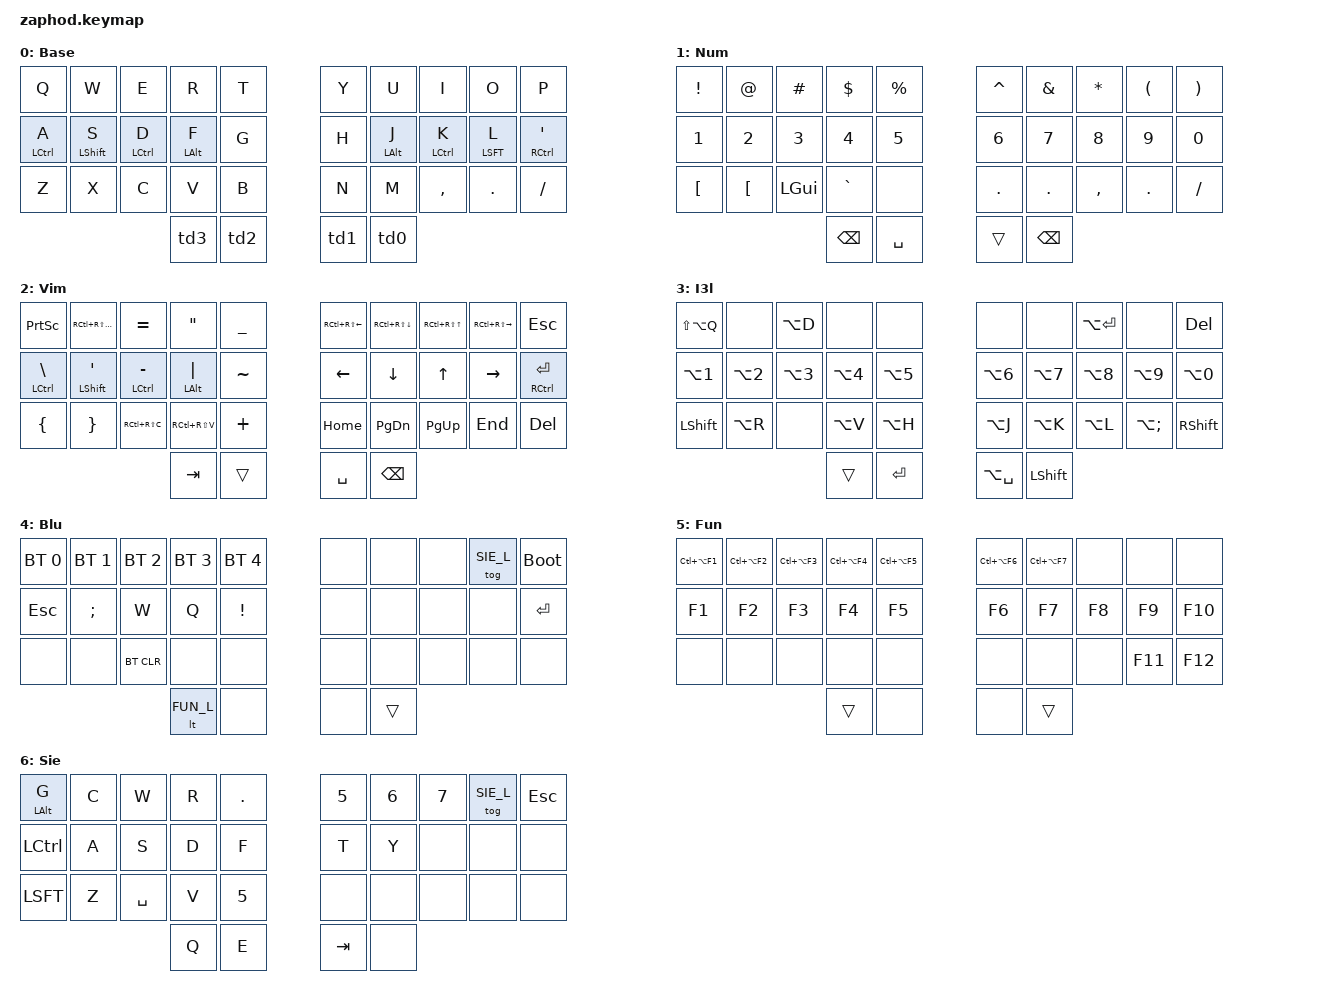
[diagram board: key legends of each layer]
/*
 * Copyright (c) 2021 Pete Johanson
 *
 * SPDX-License-Identifier: MIT
 */

#include <behaviors.dtsi>
#include <dt-bindings/zmk/keys.h>
#include <dt-bindings/zmk/bt.h>
#include <dt-bindings/zmk/outputs.h>

#define NUM_L 1
#define VIM_L 2
#define I3L_L 3
#define BLU_L 4
#define FUN_L 5
#define SIE_L 6

// Using layer taps on thumbs, having quick tap as well helps w/ repeating space/backspace
&lt { quick_tap_ms = <200>; };

/ {
    combos {
        compatible = "zmk,combos";

/*        med_mo {
 *	    timeout-ms = <50>;
 *          key-positions = <30 31>;
 *          bindings = <&mo MED_L>;
 *       };
 *
 *        fn_mo {
 *	    timeout-ms = <50>;
 *          key-positions = <32 33>;
 *          bindings = <&mo FUN_L>;
 *       };
 */
    };

    behaviors {
        hm: homerow_mods {
            compatible = "zmk,behavior-hold-tap";
            label = "homerow mods";
            #binding-cells = <2>;
            tapping_term_ms = <200>;
            flavor = "tap-preferred";
            bindings = <&kp>, <&kp>;
        };
            
        td0: tap_dance_0 {
            compatible = "zmk,behavior-tap-dance";
            label = "TAP_DANCE_0";
            #binding-cells = <0>;
            tapping-term-ms = <200>;
            bindings = <&lt BLU_L BKSP>, <&kp BKSP>;
        };
        
        td1: tap_dance_1 {
            compatible = "zmk,behavior-tap-dance";
            label = "TAP_DANCE_1";
            #binding-cells = <0>;
            tapping-term-ms = <200>;
            bindings = <&lt NUM_L SPACE>, <&kp SPACE>;
        };

        td2: tap_dance_2 {
            compatible = "zmk,behavior-tap-dance";
            label = "TAP_DANCE_2";
            #binding-cells = <0>;
            tapping-term-ms = <200>;
            bindings = <&lt VIM_L RET>, <&kp RET>;
        };

        td3: tap_dance_3 {
            compatible = "zmk,behavior-tap-dance";
            label = "TAP_DANCE_3";
            #binding-cells = <0>;
            tapping-term-ms = <200>;
            bindings = <&lt I3L_L TAB>, <&kp TAB>;
        };
    };

    keymap {
        compatible = "zmk,keymap";

        default_layer {
            label = "Base";
            bindings = <
                &kp Q       &kp W      &kp E       &kp R          &kp T         &kp Y            &kp U          &kp I       &kp O      &kp P
                &hm LCTRL A &hm LSHFT S &hm LCTRL D &hm LALT F    &kp G         &kp H            &hm LALT J     &hm LCTRL K &hm LSFT L &hm RCTRL QUOT
                &kp Z       &kp X      &kp C       &kp V          &kp B         &kp N            &kp M          &kp COMMA   &kp DOT    &kp FSLH
                                                   &td3           &td2          &td1             &td0
            >;
        };

        NUM_layer {
            label = "Num";
            bindings = <
                &kp EXCL  &kp AT    &kp POUND  &kp DLLR       &kp PRCNT   &kp CARET       &kp AMPS      &kp ASTRK  &kp LPAR  &kp RPAR
                &kp N1    &kp N2    &kp N3     &kp N4         &kp N5      &kp N6          &kp N7        &kp N8     &kp N9    &kp N0 
                &kp LBKT  &kp LBKT  &kp LGUI   &kp GRAVE      &none       &kp DOT         &kp DOT       &kp COMMA  &kp DOT   &kp FSLH
                                               &kp BKSP       &kp SPACE	  &trans          &kp BKSP
            >;
        };

        VIM_layer {
            label = "Vim";
            bindings = <
&kp PSCRN    &kp RC(RS(PSCRN)) &kp EQUAL         &kp DQT       &kp UNDER  &kp RC(RS(LEFT)) &kp RC(RS(DOWN)) &kp RC(RS(UP)) &kp RC(RS(RIGHT)) &kp ESC
&hm LCTRL BSLH  &hm LSHFT SQT  &hm LCTRL MINUS   &hm LALT PIPE &kp TILDE  &kp LEFT        &kp DOWN      &kp UP           &kp RIGHT       &hm RCTRL ENTER     
  &kp LBRC   &kp RBRC          &kp RC(RS(C))     &kp RC(RS(V)) &kp PLUS   &kp HOME        &kp PG_DN     &kp PG_UP        &kp END         &kp DEL   
                                               &kp TAB         &trans     &kp SPACE       &kp BKSP
            >;
        };

        I3L_layer {
            label = "I3l";
            bindings = <
            &kp LS(LA(Q)) &none     &kp LA(D) &none          &none        &none          &none         &kp LA(RET) &none     &kp DEL
               &kp LA(N1) &kp LA(N2) &kp LA(N3) &kp LA(N4)   &kp LA(N5)   &kp LA(N6)     &kp LA(N7)    &kp LA(N8) &kp LA(N9) &kp LA(N0)
               &kp LSHFT  &kp LA(R) &none     &kp LA(V)      &kp LA(H)    &kp LA(J)      &kp LA(K)     &kp LA(L)  &kp LA(SEMI) &kp RSHFT
                                              &trans         &kp RET      &kp LA(SPACE)  &kp LSHFT
            >;
        };

        BLU_layer {
            label = "Blu";
            bindings = <
           &bt BT_SEL 0 &bt BT_SEL 1 &bt BT_SEL 2 &bt BT_SEL 3 &bt BT_SEL 4 &none     &none     &none   &tog SIE_L  &bootloader
           &kp ESC      &kp SEMI     &kp W        &kp Q        &kp EXCL     &none     &none     &none     &none     &kp RET
           &none        &none        &bt BT_CLR   &none        &none        &none     &none     &none     &none     &none
                                                  &lt FUN_L    &none        &none     &trans
            >;
        };

        FUN_layer {
            label = "Fun";
            bindings = <
           &kp LC(LA(F1)) &kp LC(LA(F2)) &kp LC(LA(F3)) &kp LC(LA(F4)) &kp LC(LA(F5)) &kp LC(LA(F6)) &kp LC(LA(F7)) &none &none &none
           &kp F1           &kp F2           &kp F3           &kp F4           &kp F5           &kp F6           &kp F7 &kp F8    &kp F9 &kp F10
           &none            &none            &none            &none            &none            &none            &none  &none     &kp F11 &kp F12
                                                  &trans       &none        &none     &trans
            >;
        };
 
        SIE_layer {
            label = "Sie";
            bindings = <
           &hm LALT G   &kp C        &kp W        &kp R        &kp DOT      &kp N5    &kp N6    &kp N7  &tog SIE_L  &kp ESC
           &kp LCTRL    &kp A        &kp S        &kp D        &kp F        &kp T     &kp Y     &none     &none     &none
           &kp LSFT     &kp Z        &kp SPACE    &kp V        &kp N5       &none     &none     &none     &none     &none
                                                  &kp Q        &kp E        &kp TAB   &none
            >;
        };

    };
};

